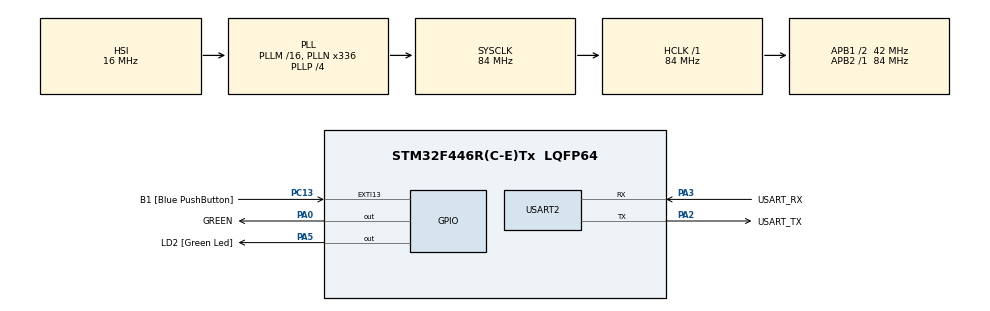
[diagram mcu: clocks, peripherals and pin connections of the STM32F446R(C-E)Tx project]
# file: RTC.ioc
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Mcu.Family=STM32F4
Mcu.Name=STM32F446R(C-E)Tx
Mcu.Package=LQFP64
NVIC.PriorityGroup=NVIC_PRIORITYGROUP_0
NVIC.RTC_Alarm_IRQn=true\:0\:0\:false\:false\:true\:true\:true
NVIC.USART2_IRQn=true\:0\:0\:false\:false\:true\:true\:true
PA0-WKUP.GPIO_Label=GREEN
PA0-WKUP.GPIO_PuPd=GPIO_PULLDOWN
PA0-WKUP.Signal=GPIO_Output
PA13.GPIO_Label=TMS
PA13.Mode=Serial_Wire
PA13.Signal=SYS_JTMS-SWDIO
PA14.GPIO_Label=TCK
PA14.Mode=Serial_Wire
PA14.Signal=SYS_JTCK-SWCLK
PA2.GPIO_Label=USART_TX
PA2.Mode=Asynchronous
PA2.Signal=USART2_TX
PA3.GPIO_Label=USART_RX
PA3.Mode=Asynchronous
PA3.Signal=USART2_RX
PA5.GPIO_Label=LD2 [Green Led]
PA5.Signal=GPIO_Output
PB3.GPIO_Label=SWO
PB3.Signal=SYS_JTDO-SWO
PC13.GPIO_Label=B1 [Blue PushButton]
PC13.GPIO_ModeDefaultEXTI=GPIO_MODE_IT_FALLING
PC13.Signal=GPXTI13
PC14-OSC32_IN.Mode=LSE-External-Oscillator
PC14-OSC32_IN.Signal=RCC_OSC32_IN
PC15-OSC32_OUT.Mode=LSE-External-Oscillator
PC15-OSC32_OUT.Signal=RCC_OSC32_OUT
PH0-OSC_IN.Mode=HSE-External-Oscillator
PH0-OSC_IN.Signal=RCC_OSC_IN
PH1-OSC_OUT.Mode=HSE-External-Oscillator
PH1-OSC_OUT.Signal=RCC_OSC_OUT
ProjectManager.HeapSize=0x200
ProjectManager.StackSize=0x400
ProjectManager.TargetToolchain=STM32CubeIDE
RCC.48MHZClocksFreq_Value=84000000
RCC.AHBFreq_Value=84000000
RCC.APB1CLKDivider=RCC_HCLK_DIV2
RCC.APB1Freq_Value=42000000
RCC.APB1TimFreq_Value=84000000
RCC.APB2Freq_Value=84000000
RCC.APB2TimFreq_Value=84000000
RCC.CortexFreq_Value=84000000
RCC.FLatency-AdvancedSettings=FLASH_LATENCY_2
RCC.HCLKFreq_Value=84000000
RCC.HSE_VALUE=8000000
RCC.HSI_VALUE=16000000
RCC.PLLN=336
RCC.PLLP=RCC_PLLP_DIV4
RCC.RCC_RTC_Clock_SourceVirtual=RCC_RTCCLKSOURCE_LSE
RCC.SYSCLKFreq_VALUE=84000000
RCC.SYSCLKSource=RCC_SYSCLKSOURCE_PLLCLK
RCC.USBFreq_Value=168000000
RCC.VCOOutputFreq_Value=336000000
RTC.Alarm=RTC_ALARM_A
RTC.AlarmDateWeekDay=11
RTC.Date=11
RTC.Hours=10
RTC.Hours_A=10
RTC.Minutes=20
RTC.Minutes_A=21
RTC.Month=RTC_MONTH_NOVEMBER
RTC.Seconds=30
RTC.WeekDay=RTC_WEEKDAY_THURSDAY
TIM2.Period=249999
TIM2.Prescaler=83
USART2.VirtualMode=VM_ASYNC
VP_RTC_VS_RTC_Activate.Mode=RTC_Enabled
VP_RTC_VS_RTC_Alarm_A_Intern.Mode=Alarm A
VP_RTC_VS_RTC_Calendar.Mode=RTC_Calendar
VP_TIM2_VS_ClockSourceINT.Mode=Internal
board=NUCLEO-F446RE

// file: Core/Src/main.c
/* USER CODE BEGIN Header */
/**
  ******************************************************************************
  * @file           : main.c
  * @brief          : Main program body
  ******************************************************************************
  * @attention
  *
  * <h2><center>&copy; Copyright (c) 2021 STMicroelectronics.
  * All rights reserved.</center></h2>
  *
  * This software component is licensed by ST under BSD 3-Clause license,
  * the "License"; You may not use this file except in compliance with the
  * License. You may obtain a copy of the License at:
  *                        opensource.org/licenses/BSD-3-Clause
  *
  ******************************************************************************
  */
/* USER CODE END Header */
#include "main.h"

RTC_HandleTypeDef hrtc;

TIM_HandleTypeDef htim2;

UART_HandleTypeDef huart2;

/* USER CODE BEGIN PV */
RTC_TimeTypeDef sTime = {0};
RTC_DateTypeDef sDate = {0};

char trans_str[64] = {0};
/* USER CODE END PV */

void SystemClock_Config(void);
static void MX_GPIO_Init(void);
static void MX_USART2_UART_Init(void);
static void MX_RTC_Init(void);
static void MX_TIM2_Init(void);
/* USER CODE BEGIN PFP */
/* USER CODE BEGIN 0 */

/* USER CODE END PFP */

/* USER CODE BEGIN 0 */

//printf function
int _write(int file, char *ptr, int len)
{
	HAL_UART_Transmit(&huart2, (uint8_t*)ptr, len, 100);
	return len;
}
/* USER CODE END PFP */

/* Private user code ---------------------------------------------------------*/
/* USER CODE BEGIN 0 */

/* USER CODE END 0 */

int main(void)
{

  /* MCU Configuration--------------------------------------------------------*/

  /* Reset of all peripherals, Initializes the Flash interface and the Systick. */
  HAL_Init();

  /* Configure the system clock */
  SystemClock_Config();

  /* Initialize all configured peripherals */
  MX_GPIO_Init();
  MX_USART2_UART_Init();
  MX_RTC_Init();
  MX_TIM2_Init();
  /* USER CODE BEGIN 2 */

  //start
  HAL_TIM_Base_Start_IT(&htim2);
  /* USER CODE END 2 */

  /* Infinite loop */
  /* USER CODE BEGIN WHILE */
  while (1)
  {
	  //HAL_RTC_GetTime(&hrtc, &sTime, RTC_FORMAT_BIN); // RTC_FORMAT_BIN , RTC_FORMAT_BCD
	  //printf("sdfsd");
	  //HAL_Delay(1000);
    /* USER CODE END WHILE */

  }
}

void SystemClock_Config(void)
{
  RCC_OscInitTypeDef RCC_OscInitStruct = {0};
  RCC_ClkInitTypeDef RCC_ClkInitStruct = {0};

  /** Configure the main internal regulator output voltage
  */
  __HAL_RCC_PWR_CLK_ENABLE();
  __HAL_PWR_VOLTAGESCALING_CONFIG(PWR_REGULATOR_VOLTAGE_SCALE3);
  /** Initializes the RCC Oscillators according to the specified parameters
  * in the RCC_OscInitTypeDef structure.
  */
  RCC_OscInitStruct.OscillatorType = RCC_OSCILLATORTYPE_HSI|RCC_OSCILLATORTYPE_LSE;
  RCC_OscInitStruct.LSEState = RCC_LSE_ON;
  RCC_OscInitStruct.HSIState = RCC_HSI_ON;
  RCC_OscInitStruct.HSICalibrationValue = RCC_HSICALIBRATION_DEFAULT;
  RCC_OscInitStruct.PLL.PLLState = RCC_PLL_ON;
  RCC_OscInitStruct.PLL.PLLSource = RCC_PLLSOURCE_HSI;
  RCC_OscInitStruct.PLL.PLLM = 16;
  RCC_OscInitStruct.PLL.PLLN = 336;
  RCC_OscInitStruct.PLL.PLLP = RCC_PLLP_DIV4;
  RCC_OscInitStruct.PLL.PLLQ = 2;
  RCC_OscInitStruct.PLL.PLLR = 2;
  if (HAL_RCC_OscConfig(&RCC_OscInitStruct) != HAL_OK)
  {
    Error_Handler();
  }
  /** Initializes the CPU, AHB and APB buses clocks
  */
  RCC_ClkInitStruct.ClockType = RCC_CLOCKTYPE_HCLK|RCC_CLOCKTYPE_SYSCLK
                              |RCC_CLOCKTYPE_PCLK1|RCC_CLOCKTYPE_PCLK2;
  RCC_ClkInitStruct.SYSCLKSource = RCC_SYSCLKSOURCE_PLLCLK;
  RCC_ClkInitStruct.AHBCLKDivider = RCC_SYSCLK_DIV1;
  RCC_ClkInitStruct.APB1CLKDivider = RCC_HCLK_DIV2;
  RCC_ClkInitStruct.APB2CLKDivider = RCC_HCLK_DIV1;

  if (HAL_RCC_ClockConfig(&RCC_ClkInitStruct, FLASH_LATENCY_2) != HAL_OK)
  {
    Error_Handler();
  }
}

static void MX_RTC_Init(void)
{

  RTC_TimeTypeDef sTime = {0};
  RTC_DateTypeDef sDate = {0};
  RTC_AlarmTypeDef sAlarm = {0};

  /** Initialize RTC Only
  */
  hrtc.Instance = RTC;
  hrtc.Init.HourFormat = RTC_HOURFORMAT_24;
  hrtc.Init.AsynchPrediv = 127;
  hrtc.Init.SynchPrediv = 255;
  hrtc.Init.OutPut = RTC_OUTPUT_DISABLE;
  hrtc.Init.OutPutPolarity = RTC_OUTPUT_POLARITY_HIGH;
  hrtc.Init.OutPutType = RTC_OUTPUT_TYPE_OPENDRAIN;
  if (HAL_RTC_Init(&hrtc) != HAL_OK)
  {
    Error_Handler();
  }

  /** Initialize RTC and set the Time and Date
  */
  sTime.Hours = 0x10;
  sTime.Minutes = 0x20;
  sTime.Seconds = 0x30;
  sTime.DayLightSaving = RTC_DAYLIGHTSAVING_NONE;
  sTime.StoreOperation = RTC_STOREOPERATION_RESET;
  if (HAL_RTC_SetTime(&hrtc, &sTime, RTC_FORMAT_BCD) != HAL_OK)
  {
    Error_Handler();
  }
  sDate.WeekDay = RTC_WEEKDAY_THURSDAY;
  sDate.Month = RTC_MONTH_NOVEMBER;
  sDate.Date = 0x11;
  sDate.Year = 0x0;

  if (HAL_RTC_SetDate(&hrtc, &sDate, RTC_FORMAT_BCD) != HAL_OK)
  {
    Error_Handler();
  }
  /** Enable the Alarm A
  */
  sAlarm.AlarmTime.Hours = 0x10;
  sAlarm.AlarmTime.Minutes = 0x21;
  sAlarm.AlarmTime.Seconds = 0x0;
  sAlarm.AlarmTime.SubSeconds = 0x0;
  sAlarm.AlarmTime.DayLightSaving = RTC_DAYLIGHTSAVING_NONE;
  sAlarm.AlarmTime.StoreOperation = RTC_STOREOPERATION_RESET;
  sAlarm.AlarmMask = RTC_ALARMMASK_NONE;
  sAlarm.AlarmSubSecondMask = RTC_ALARMSUBSECONDMASK_ALL;
  sAlarm.AlarmDateWeekDaySel = RTC_ALARMDATEWEEKDAYSEL_DATE;
  sAlarm.AlarmDateWeekDay = 0x11;
  sAlarm.Alarm = RTC_ALARM_A;
  if (HAL_RTC_SetAlarm_IT(&hrtc, &sAlarm, RTC_FORMAT_BCD) != HAL_OK)
  {
    Error_Handler();
  }
  /* USER CODE BEGIN RTC_Init 2 */

  //Backup register to store TIME and DATE
  //HAL_RTCEx_BKUPWrite(&hrtc, RTC_BKP_DR1, 0x32F2);

  /* USER CODE END RTC_Init 2 */

}

static void MX_TIM2_Init(void)
{

  TIM_ClockConfigTypeDef sClockSourceConfig = {0};
  TIM_MasterConfigTypeDef sMasterConfig = {0};

  htim2.Instance = TIM2;
  htim2.Init.Prescaler = 83;
  htim2.Init.CounterMode = TIM_COUNTERMODE_UP;
  htim2.Init.Period = 249999;
  htim2.Init.ClockDivision = TIM_CLOCKDIVISION_DIV1;
  htim2.Init.AutoReloadPreload = TIM_AUTORELOAD_PRELOAD_DISABLE;
  if (HAL_TIM_Base_Init(&htim2) != HAL_OK)
  {
    Error_Handler();
  }
  sClockSourceConfig.ClockSource = TIM_CLOCKSOURCE_INTERNAL;
  if (HAL_TIM_ConfigClockSource(&htim2, &sClockSourceConfig) != HAL_OK)
  {
    Error_Handler();
  }
  sMasterConfig.MasterOutputTrigger = TIM_TRGO_RESET;
  sMasterConfig.MasterSlaveMode = TIM_MASTERSLAVEMODE_DISABLE;
  if (HAL_TIMEx_MasterConfigSynchronization(&htim2, &sMasterConfig) != HAL_OK)
  {
    Error_Handler();
  }

}

static void MX_USART2_UART_Init(void)
{

  huart2.Instance = USART2;
  huart2.Init.BaudRate = 115200;
  huart2.Init.WordLength = UART_WORDLENGTH_8B;
  huart2.Init.StopBits = UART_STOPBITS_1;
  huart2.Init.Parity = UART_PARITY_NONE;
  huart2.Init.Mode = UART_MODE_TX_RX;
  huart2.Init.HwFlowCtl = UART_HWCONTROL_NONE;
  huart2.Init.OverSampling = UART_OVERSAMPLING_16;
  if (HAL_UART_Init(&huart2) != HAL_OK)
  {
    Error_Handler();
  }

}

static void MX_GPIO_Init(void)
{
  GPIO_InitTypeDef GPIO_InitStruct = {0};

  /* GPIO Ports Clock Enable */
  __HAL_RCC_GPIOC_CLK_ENABLE();
  __HAL_RCC_GPIOH_CLK_ENABLE();
  __HAL_RCC_GPIOA_CLK_ENABLE();
  __HAL_RCC_GPIOB_CLK_ENABLE();

  /*Configure GPIO pin Output Level */
  HAL_GPIO_WritePin(GPIOA, GREEN_Pin|LD2_Pin, GPIO_PIN_RESET);

  /*Configure GPIO pin : B1_Pin */
  GPIO_InitStruct.Pin = B1_Pin;
  GPIO_InitStruct.Mode = GPIO_MODE_IT_FALLING;
  GPIO_InitStruct.Pull = GPIO_NOPULL;
  HAL_GPIO_Init(B1_GPIO_Port, &GPIO_InitStruct);

  /*Configure GPIO pin : GREEN_Pin */
  GPIO_InitStruct.Pin = GREEN_Pin;
  GPIO_InitStruct.Mode = GPIO_MODE_OUTPUT_PP;
  GPIO_InitStruct.Pull = GPIO_PULLDOWN;
  GPIO_InitStruct.Speed = GPIO_SPEED_FREQ_LOW;
  HAL_GPIO_Init(GREEN_GPIO_Port, &GPIO_InitStruct);

  /*Configure GPIO pin : LD2_Pin */
  GPIO_InitStruct.Pin = LD2_Pin;
  GPIO_InitStruct.Mode = GPIO_MODE_OUTPUT_PP;
  GPIO_InitStruct.Pull = GPIO_NOPULL;
  GPIO_InitStruct.Speed = GPIO_SPEED_FREQ_LOW;
  HAL_GPIO_Init(LD2_GPIO_Port, &GPIO_InitStruct);

}

/* USER CODE BEGIN 4 */
void HAL_TIM_PeriodElapsedCallback(TIM_HandleTypeDef *htim)
{
	if (htim->Instance == TIM2) //If the source is TIM2
	{
		  HAL_GPIO_TogglePin(LD2_GPIO_Port, LD2_Pin);
	}
}
/* USER CODE END 4 */

void Error_Handler(void)
{
  __disable_irq();
  while (1)
  {
  }
}

/************************ (C) COPYRIGHT STMicroelectronics *****END OF FILE****/
